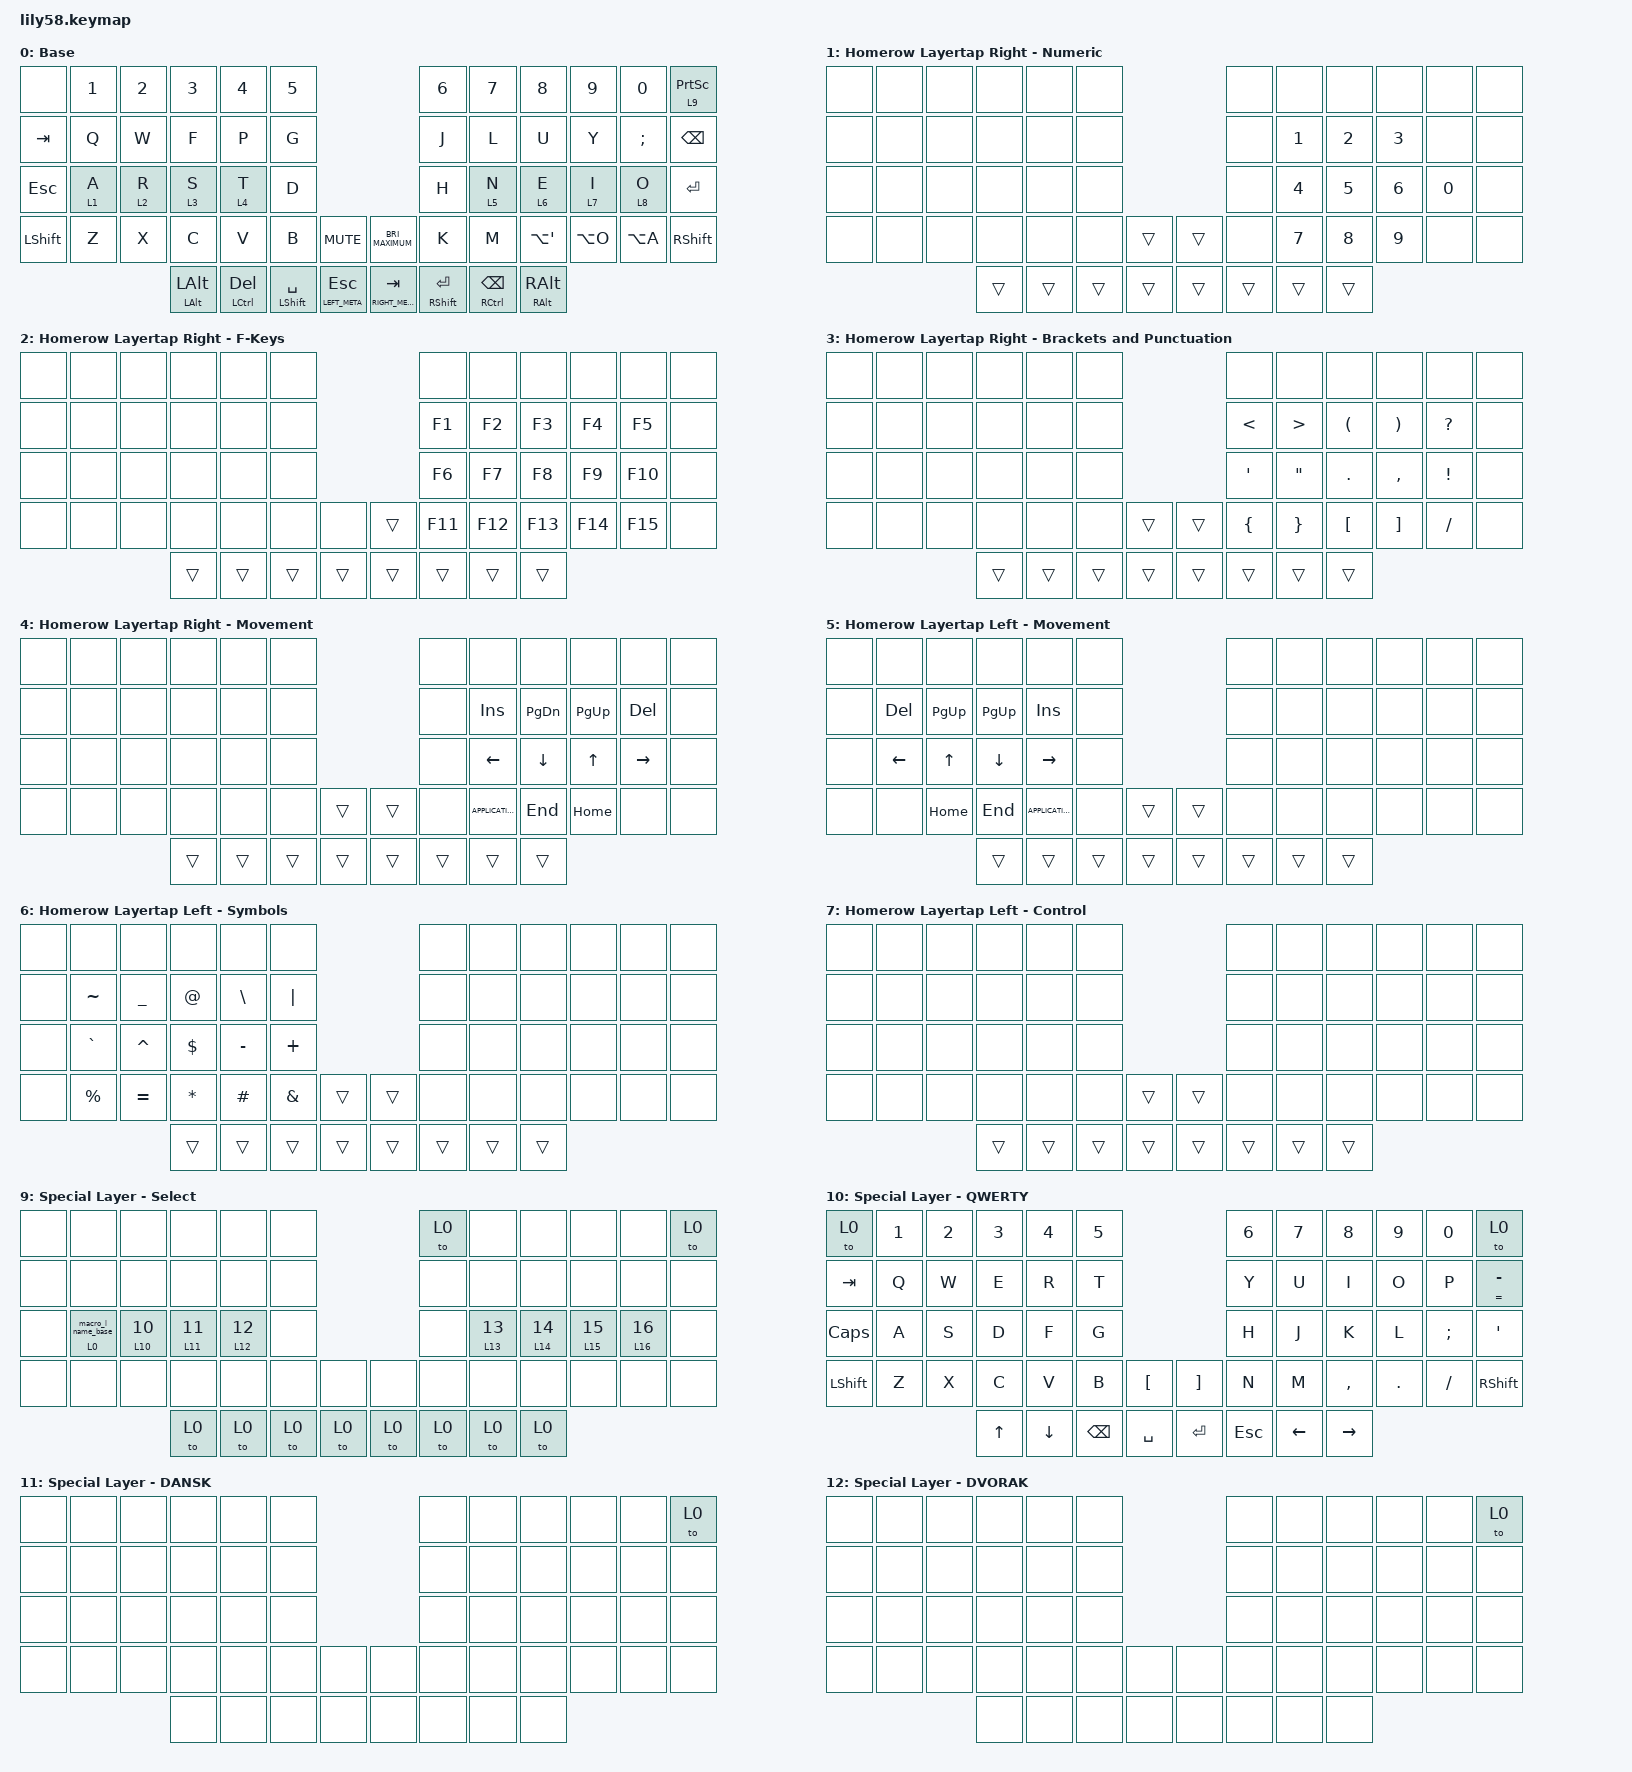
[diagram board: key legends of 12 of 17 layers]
#include <behaviors.dtsi>
#include <dt-bindings/zmk/keys.h>

#define LEFT_HAND_KEYS 0 1 2 4 5 12 13 14 15 16 17 24 25 26 27 28 29 36 37 38 39 40 41 3
#define RIGHT_HAND_KEYS 6 10 11 18 19 20 21 22 23 30 31 32 33 34 35 44 45 46 47 48 49 7 8 9
#define THUMB_KEYS 54 57 56 55 43 42 50 51 52 53
#define HOMEROW_LAYERTAP_TAPPING_TERM 250
#define HOMEROW_LAYERTAP_QUICK_TAP 150
#define HOMEROW_LAYER_SELECT_TAP 1000

/ {
    behaviors {
        // "Timeless Homerow Mods", as described by urob
        // https://github.com/urob/zmk-config#timeless-homerow-mods

        hmltr: behavior_homerow_layertap_right {
            compatible = "zmk,behavior-hold-tap";
            label = "BEHAVIOR_HOMEROW_LAYERTAP_RIGHT";
            hold-trigger-key-positions = <LEFT_HAND_KEYS THUMB_KEYS>;
            #binding-cells = <2>;
            flavor = "balanced";
            global-quick-tap;
            tapping-term-ms = <HOMEROW_LAYERTAP_TAPPING_TERM>;
            quick-tap-ms = <HOMEROW_LAYERTAP_QUICK_TAP>;
            hold-trigger-on-release;
            bindings =
                <&mo>,
                <&kp>;
        };
        hmltl: behavior_homerow_layertap_left {
            compatible = "zmk,behavior-hold-tap";
            label = "BEHAVIOR_HOMEROW_LAYERTAP_LEFT";
            hold-trigger-key-positions = <RIGHT_HAND_KEYS THUMB_KEYS>;
            #binding-cells = <2>;
            flavor = "balanced";
            global-quick-tap;
            tapping-term-ms = <HOMEROW_LAYERTAP_TAPPING_TERM>;
            quick-tap-ms = <HOMEROW_LAYERTAP_QUICK_TAP>;
            hold-trigger-on-release;
            bindings =
                <&mo>,
                <&kp>;
        };

        // Configuration for thumb-key mods

        tm: behavior_thumbmod {
            compatible = "zmk,behavior-hold-tap";
            label = "BEHAVIOR_HOMEROW_LAYERTAP_THUMB";
            hold-trigger-key-positions = <LEFT_HAND_KEYS RIGHT_HAND_KEYS>;
            #binding-cells = <2>;
            flavor = "balanced";
            global-quick-tap;
            tapping-term-ms = <HOMEROW_LAYERTAP_TAPPING_TERM>;
            quick-tap-ms = <HOMEROW_LAYERTAP_QUICK_TAP>;
            hold-trigger-on-release;
            bindings =
                <&kp>,
                <&kp>;
        };
        tmr: behavior_thumbmod_repeat {
            compatible = "zmk,behavior-hold-tap";
            label = "BEHAVIOR_HOMEROW_LAYERTAP_THUMB_REPEAT";
            hold-trigger-key-positions = <LEFT_HAND_KEYS RIGHT_HAND_KEYS>;
            #binding-cells = <2>;
            flavor = "balanced";
            global-quick-tap;
            tapping-term-ms = <HOMEROW_LAYERTAP_TAPPING_TERM>;
            quick-tap-ms = <HOMEROW_LAYERTAP_QUICK_TAP>;
            hold-trigger-on-release;
            bindings =
                <&kp>,
                <&key_repeat>;
        };

        // Configuration for special layers

        behavior_select_base: behavior_select_base {
            label = "behavior_select_base";
            compatible = "zmk,behavior-hold-tap";
            #binding-cells = <2>;
            flavor = "balanced";

            tapping-term-ms = <HOMEROW_LAYER_SELECT_TAP>;
            bindings =
                <&to>,
                <&macro_l_name_base>;
        };
        behavior_select_s_alpha: behavior_select_s_alpha {
            label = "behavior_select_s_alpha";
            compatible = "zmk,behavior-hold-tap";
            #binding-cells = <2>;
            flavor = "balanced";

            tapping-term-ms = <HOMEROW_LAYER_SELECT_TAP>;
            bindings =
                <&to>,
                <&macro_l_name_s_alpha>;
        };
        behavior_select_s_beta: behavior_select_s_beta {
            label = "behavior_select_s_beta";
            compatible = "zmk,behavior-hold-tap";
            #binding-cells = <2>;
            flavor = "balanced";

            tapping-term-ms = <HOMEROW_LAYER_SELECT_TAP>;
            bindings =
                <&to>,
                <&macro_l_name_s_beta>;
        };
        behavior_select_s_gamma: behavior_select_s_gamma {
            label = "behavior_select_s_gamma";
            compatible = "zmk,behavior-hold-tap";
            #binding-cells = <2>;
            flavor = "balanced";

            tapping-term-ms = <HOMEROW_LAYER_SELECT_TAP>;
            bindings =
                <&to>,
                <&macro_l_name_s_gamma>;
        };
        behavior_select_s_delta: behavior_select_s_delta {
            label = "behavior_select_s_delta";
            compatible = "zmk,behavior-hold-tap";
            #binding-cells = <2>;
            flavor = "balanced";

            tapping-term-ms = <HOMEROW_LAYER_SELECT_TAP>;
            bindings =
                <&to>,
                <&macro_l_name_s_delta>;
        };
        behavior_select_s_epsilon: behavior_select_s_epsilon {
            label = "behavior_select_s_epsilon";
            compatible = "zmk,behavior-hold-tap";
            #binding-cells = <2>;
            flavor = "balanced";

            tapping-term-ms = <HOMEROW_LAYER_SELECT_TAP>;
            bindings =
                <&to>,
                <&macro_l_name_s_epsilon>;
        };
        behavior_select_s_zeta: behavior_select_s_zeta {
            label = "behavior_select_s_zeta";
            compatible = "zmk,behavior-hold-tap";
            #binding-cells = <2>;
            flavor = "balanced";

            tapping-term-ms = <HOMEROW_LAYER_SELECT_TAP>;
            bindings =
                <&to>,
                <&macro_l_name_s_zeta>;
        };
        behavior_select_s_eta: behavior_select_s_eta {
            label = "behavior_select_s_eta";
            compatible = "zmk,behavior-hold-tap";
            #binding-cells = <2>;
            flavor = "balanced";

            tapping-term-ms = <HOMEROW_LAYER_SELECT_TAP>;
            bindings =
                <&to>,
                <&macro_l_name_s_eta>;
        };
        behavior_select_s_theta: behavior_select_s_theta {
            label = "behavior_select_s_theta";
            compatible = "zmk,behavior-hold-tap";
            #binding-cells = <2>;
            flavor = "balanced";

            tapping-term-ms = <HOMEROW_LAYER_SELECT_TAP>;
            bindings =
                <&to>,
                <&macro_l_name_s_theta>;
        };
    };

    macros {
        // Macros to print the names of special layers

        macro_l_name_base: macro_l_name_base {
            label = "Layer Name Base";
            compatible = "zmk,behavior-macro";
            #binding-cells = <0>;
            bindings =
                <&macro_tap>,
                <&kp B &kp A &kp S &kp E>;
        };
        macro_l_name_s_alpha: macro_l_name_s_alpha {
            label = "Layer Name Special Alpha";
            compatible = "zmk,behavior-macro";
            #binding-cells = <0>;
            bindings =
                <&macro_tap>,
                <&kp S &kp E &kp L &kp E &kp C &kp T>;
        };
        macro_l_name_s_beta: macro_l_name_s_beta {
            label = "Layer Name Special Beta";
            compatible = "zmk,behavior-macro";
            #binding-cells = <0>;
            bindings =
                <&macro_tap>,
                <&kp Q &kp W &kp E &kp R &kp T &kp Y>;
        };
        macro_l_name_s_gamma: macro_l_name_s_gamma {
            label = "Layer Name Special Gamma";
            compatible = "zmk,behavior-macro";
            #binding-cells = <0>;
            bindings =
                <&macro_tap>,
                <&kp D &kp A &kp N &kp S &kp K>;
        };
        macro_l_name_s_delta: macro_l_name_s_delta {
            label = "Layer Name Special Delta";
            compatible = "zmk,behavior-macro";
            #binding-cells = <0>;
            bindings =
                <&macro_tap>,
                <&kp D &kp V &kp O &kp R &kp A &kp K>;
        };
        macro_l_name_s_epsilon: macro_l_name_s_epsilon {
            label = "Layer Name Special Epsilon";
            compatible = "zmk,behavior-macro";
            #binding-cells = <0>;
            bindings =
                <&macro_tap>,
                <&kp C &kp O &kp L &kp E &kp M &kp A &kp K>;
        };
        macro_l_name_s_zeta: macro_l_name_s_zeta {
            label = "Layer Name Special Zeta";
            compatible = "zmk,behavior-macro";
            #binding-cells = <0>;
            bindings =
                <&macro_tap>,
                <&kp G &kp A &kp M &kp I &kp N &kp G>;
        };
        macro_l_name_s_eta: macro_l_name_s_eta {
            label = "Layer Name Special Eta";
            compatible = "zmk,behavior-macro";
            #binding-cells = <0>;
            bindings =
                <&macro_tap>,
                <&kp B &kp L &kp O &kp O &kp M>;
        };
        macro_l_name_s_theta: macro_l_name_s_theta {
            label = "Layer Name Special Theta";
            compatible = "zmk,behavior-macro";
            #binding-cells = <0>;
            bindings =
                <&macro_tap>,
                <&kp C &kp O &kp N &kp T &kp R &kp O &kp L>;
        };
    };

    keymap {
        compatible = "zmk,keymap";

        layer_base {
            label = "Base";
            bindings = <
     &none      &kp N1      &kp N2                  &kp N3                   &kp N4                &kp N5                                                                   &kp N6                       &kp N7                    &kp N8      &kp N9         &kp N0  &lt 9 PRINTSCREEN
   &kp TAB       &kp Q       &kp W                   &kp F                    &kp P                 &kp G                                                                    &kp J                        &kp L                     &kp U       &kp Y  &kp SEMICOLON      &kp BACKSPACE
&kp ESCAPE  &hmltl 1 A  &hmltl 2 R              &hmltl 3 S               &hmltl 4 T                 &kp D                                                                    &kp H                   &hmltr 5 N                &hmltr 6 E  &hmltr 7 I     &hmltr 8 O          &kp ENTER
 &kp LSHFT       &kp Z       &kp X                   &kp C                    &kp V                 &kp B            &kp K_MUTE    &kp C_BRIGHTNESS_MAXIMUM                  &kp K                        &kp M      &kp LA(SINGLE_QUOTE)   &kp LA(O)      &kp LA(A)          &kp RSHFT
                                    &tmr LEFT_ALT LEFT_ALT  &tm LEFT_CONTROL DELETE  &tm LEFT_SHIFT SPACE  &tm LEFT_META ESCAPE          &tm RIGHT_META TAB  &tm RIGHT_SHIFT ENTER  &tm RIGHT_CONTROL BACKSPACE  &tmr RIGHT_ALT RIGHT_ALT
            >;

            sensor-bindings = <&inc_dec_kp C_VOL_UP C_VOL_DN>;
        };

        layer_homerow_layertap_alpha {
            label = "Homerow Layertap Right - Numeric";
            bindings = <
&none  &none  &none   &none   &none   &none                     &none         &none         &none         &none         &none  &none
&none  &none  &none   &none   &none   &none                     &none  &kp NUMBER_1  &kp NUMBER_2  &kp NUMBER_3         &none  &none
&none  &none  &none   &none   &none   &none                     &none  &kp NUMBER_4  &kp NUMBER_5  &kp NUMBER_6  &kp NUMBER_0  &none
&none  &none  &none   &none   &none   &none  &trans    &trans   &none  &kp NUMBER_7  &kp NUMBER_8  &kp NUMBER_9         &none  &none
                     &trans  &trans  &trans  &trans    &trans  &trans        &trans        &trans
            >;
        };

        layer_homerow_layertap_beta {
            label = "Homerow Layertap Right - F-Keys";
            bindings = <
&none  &none  &none   &none   &none   &none                      &none    &none    &none    &none    &none  &none
&none  &none  &none   &none   &none   &none                     &kp F1   &kp F2   &kp F3   &kp F4   &kp F5  &none
&none  &none  &none   &none   &none   &none                     &kp F6   &kp F7   &kp F8   &kp F9  &kp F10  &none
&none  &none  &none   &none   &none   &none   &none    &trans  &kp F11  &kp F12  &kp F13  &kp F14  &kp F15  &none
                     &trans  &trans  &trans  &trans    &trans   &trans   &trans   &trans
            >;
        };

        layer_homerow_layertap_gamma {
            label = "Homerow Layertap Right - Brackets and Punctuation";
            bindings = <
&none  &none  &none   &none   &none   &none                               &none              &none                 &none                  &none            &none  &none
&none  &none  &none   &none   &none   &none                       &kp LESS_THAN   &kp GREATER_THAN  &kp LEFT_PARENTHESIS  &kp RIGHT_PARENTHESIS     &kp QUESTION  &none
&none  &none  &none   &none   &none   &none                    &kp SINGLE_QUOTE  &kp DOUBLE_QUOTES            &kp PERIOD              &kp COMMA  &kp EXCLAMATION  &none
&none  &none  &none   &none   &none   &none  &trans    &trans    &kp LEFT_BRACE    &kp RIGHT_BRACE      &kp LEFT_BRACKET      &kp RIGHT_BRACKET        &kp SLASH  &none
                     &trans  &trans  &trans  &trans    &trans            &trans             &trans                &trans
            >;
        };

        layer_homerow_layertap_delta {
            label = "Homerow Layertap Right - Movement";
            bindings = <
&none  &none  &none   &none   &none   &none                     &none              &none      &none      &none       &none  &none
&none  &none  &none   &none   &none   &none                     &none         &kp INSERT  &kp PG_DN  &kp PG_UP  &kp DELETE  &none
&none  &none  &none   &none   &none   &none                     &none           &kp LEFT   &kp DOWN     &kp UP   &kp RIGHT  &none
&none  &none  &none   &none   &none   &none  &trans    &trans   &none  &kp K_APPLICATION    &kp END   &kp HOME       &none  &none
                     &trans  &trans  &trans  &trans    &trans  &trans             &trans     &trans
            >;
        };

        layer_homerow_layertap_epsilon {
            label = "Homerow Layertap Left - Movement";
            bindings = <
&none       &none         &none      &none              &none   &none                     &none   &none   &none  &none  &none  &none
&none  &kp DELETE     &kp PG_UP  &kp PG_UP         &kp INSERT   &none                     &none   &none   &none  &none  &none  &none
&none    &kp LEFT  &kp UP_ARROW   &kp DOWN          &kp RIGHT   &none                     &none   &none   &none  &none  &none  &none
&none       &none      &kp HOME    &kp END  &kp K_APPLICATION   &none  &trans    &trans   &none   &none   &none  &none  &none  &none
                                    &trans             &trans  &trans  &trans    &trans  &trans  &trans  &trans
            >;
        };

        layer_homerow_layertap_zeta {
            label = "Homerow Layertap Left - Symbols";
            bindings = <
&none        &none           &none         &none          &none          &none                     &none   &none   &none  &none  &none  &none
&none    &kp TILDE  &kp UNDERSCORE   &kp AT_SIGN  &kp BACKSLASH       &kp PIPE                     &none   &none   &none  &none  &none  &none
&none    &kp GRAVE       &kp CARET    &kp DOLLAR      &kp MINUS       &kp PLUS                     &none   &none   &none  &none  &none  &none
&none  &kp PERCENT       &kp EQUAL  &kp ASTERISK       &kp HASH  &kp AMPERSAND  &trans    &trans   &none   &none   &none  &none  &none  &none
                                          &trans         &trans         &trans  &trans    &trans  &trans  &trans  &trans
            >;
        };

        layer_homerow_layertap_eta {
            label = "Homerow Layertap Left - Control";
            bindings = <
&none  &none  &none   &none   &none   &none                     &none   &none   &none  &none  &none  &none
&none  &none  &none   &none   &none   &none                     &none   &none   &none  &none  &none  &none
&none  &none  &none   &none   &none   &none                     &none   &none   &none  &none  &none  &none
&none  &none  &none   &none   &none   &none  &trans    &trans   &none   &none   &none  &none  &none  &none
                     &trans  &trans  &trans  &trans    &trans  &trans  &trans  &trans
            >;
        };

        layer_homerow_layertap_theta {
            label = "Homerow Layertap Left - Numeric";
            bindings = <
&none         &none         &none         &none         &none  &none                    &none  &none  &none  &none  &none  &none
&none         &none  &kp NUMBER_1  &kp NUMBER_2  &kp NUMBER_3  &none                    &none  &none  &none  &none  &none  &none
&none  &kp NUMBER_0  &kp NUMBER_4  &kp NUMBER_5  &kp NUMBER_6  &none                    &none  &none  &none  &none  &none  &none
&none         &none  &kp NUMBER_7  &kp NUMBER_8  &kp NUMBER_9  &none  &trans    &trans
            >;
        };

        layer_special_alpha {
            label = "Special Layer - Select";
            bindings = <
&none                      &none                          &none                           &none                           &none  &none                  &to 0                             &none                          &none                         &none                           &none  &to 0
&none                      &none                          &none                           &none                           &none  &none                  &none                             &none                          &none                         &none                           &none  &none
&none  &behavior_select_base 0 0  &behavior_select_s_beta 10 10  &behavior_select_s_gamma 11 11  &behavior_select_s_delta 12 12  &none                  &none  &behavior_select_s_epsilon 13 13  &behavior_select_s_zeta 14 14  &behavior_select_s_eta 15 15  &behavior_select_s_theta 16 16  &none
&none                      &none                          &none                           &none                           &none  &none  &none    &none  &none                             &none                          &none                         &none                           &none  &none
                                                                                          &to 0                           &to 0  &to 0  &to 0    &to 0  &to 0                             &to 0                          &to 0
            >;
        };

        layer_special_beta {
            label = "Special Layer - QWERTY";
            bindings = <
    &to 0  &kp N1  &kp N2  &kp N3    &kp N4    &kp N5                                      &kp N6    &kp N7     &kp N8   &kp N9    &kp N0            &to 0
  &kp TAB   &kp Q   &kp W   &kp E     &kp R     &kp T                                       &kp Y     &kp U      &kp I    &kp O     &kp P  &mt EQUAL MINUS
 &kp CAPS   &kp A   &kp S   &kp D     &kp F     &kp G                                       &kp H     &kp J      &kp K    &kp L  &kp SEMI          &kp SQT
&kp LSHFT   &kp Z   &kp X   &kp C     &kp V     &kp B   &kp LBKT    &kp RIGHT_BRACKET       &kp N     &kp M  &kp COMMA  &kp DOT  &kp FSLH        &kp RSHFT
                           &kp UP  &kp DOWN  &kp BSPC  &kp SPACE              &kp RET  &kp ESCAPE  &kp LEFT  &kp RIGHT
            >;
        };

        layer_special_gamma {
            label = "Special Layer - DANSK";
            bindings = <
&none  &none  &none  &none  &none  &none                  &none  &none  &none  &none  &none  &to 0
&none  &none  &none  &none  &none  &none                  &none  &none  &none  &none  &none  &none
&none  &none  &none  &none  &none  &none                  &none  &none  &none  &none  &none  &none
&none  &none  &none  &none  &none  &none  &none    &none  &none  &none  &none  &none  &none  &none
                     &none  &none  &none  &none    &none  &none  &none  &none
            >;
        };

        layer_special_delta {
            label = "Special Layer - DVORAK";
            bindings = <
&none  &none  &none  &none  &none  &none                  &none  &none  &none  &none  &none  &to 0
&none  &none  &none  &none  &none  &none                  &none  &none  &none  &none  &none  &none
&none  &none  &none  &none  &none  &none                  &none  &none  &none  &none  &none  &none
&none  &none  &none  &none  &none  &none  &none    &none  &none  &none  &none  &none  &none  &none
                     &none  &none  &none  &none    &none  &none  &none  &none
            >;
        };

        layer_special_epsilon {
            label = "Special Layer - COLEMAK";
            bindings = <
&none  &none  &none  &none  &none  &none                  &none  &none  &none  &none  &none  &to 0
&none  &none  &none  &none  &none  &none                  &none  &none  &none  &none  &none  &none
&none  &none  &none  &none  &none  &none                  &none  &none  &none  &none  &none  &none
&none  &none  &none  &none  &none  &none  &none    &none  &none  &none  &none  &none  &none  &none
                     &none  &none  &none  &none    &none  &none  &none  &none
            >;
        };

        layer_special_zeta {
            label = "Special Layer - Gaming";
            bindings = <
&lt 0 NUMBER_5   &kp N6  &kp NUMBER_1              &kp N2      &kp N3     &kp N4                      &none  &none  &none  &none  &none  &to 0
      &kp CLCK  &kp TAB         &kp Q               &kp W       &kp E      &kp R                      &none  &none  &none  &none  &none  &none
     &kp LCTRL    &kp I         &kp A               &kp S       &kp D      &kp F                      &none  &none  &none  &none  &none  &none
     &kp ENTER    &kp G         &kp Z               &kp X       &kp C      &kp V      &none    &none  &none  &none  &none  &none  &none  &none
                                       &mt F1 PRINTSCREEN  &kp ESCAPE  &kp RSHFT  &kp SPACE    &none  &none  &none  &none
            >;
        };

        layer_special_eta {
            label = "Special Layer - Bloom";
            bindings = <
&none  &none  &none  &none  &none  &none                  &none  &none  &none  &none  &none  &to 0
&none  &none  &none  &none  &none  &none                  &none  &none  &none  &none  &none  &none
&none  &none  &none  &none  &none  &none                  &none  &none  &none  &none  &none  &none
&none  &none  &none  &none  &none  &none  &none    &none  &none  &none  &none  &none  &none  &none
                     &none  &none  &none  &none    &none  &none  &none  &none
            >;
        };

        layer_special_theta {
            label = "Special Layer - Control";
            bindings = <
&none  &none  &none  &none  &none  &none                  &none  &none  &none  &none  &none  &to 0
&none  &none  &none  &none  &none  &none                  &none  &none  &none  &none  &none  &none
&none  &none  &none  &none  &none  &none                  &none  &none  &none  &none  &none  &none
&none  &none  &none  &none  &none  &none  &none    &none  &none  &none  &none  &none  &none  &none
                     &none  &none  &none  &none    &none  &none  &none  &none
            >;
        };
    };
};
